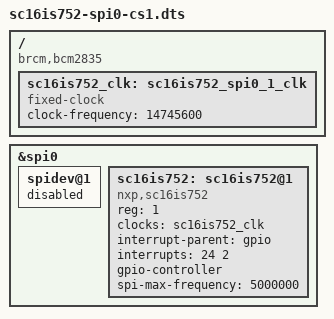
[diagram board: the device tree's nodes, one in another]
/dts-v1/;
/plugin/;

/ {
	compatible = "brcm,bcm2835";

	fragment@0 {
		target = <&spi0>;
		__overlay__ {
			#address-cells = <1>;
			#size-cells = <0>;
			status = "okay";
            
                        spidev@1{
                                status = "disabled";
                        };

			sc16is752: sc16is752@1 {
				compatible = "nxp,sc16is752";
				reg = <1>; /* CE0 */
				clocks = <&sc16is752_clk>;
				interrupt-parent = <&gpio>;
				interrupts = <24 2>; /* IRQ_TYPE_EDGE_FALLING */
				gpio-controller;
				#gpio-cells = <2>;
				spi-max-frequency = <5000000>;
			};
		};
	};


	fragment@1 {
		target-path = "/";
		__overlay__ {
			sc16is752_clk: sc16is752_spi0_1_clk {
				compatible = "fixed-clock";
				#clock-cells = <0>;
				clock-frequency = <14745600>;
			};
		};
	};

	__overrides__ {
		int_pin = <&sc16is752>,"interrupts:0";
		xtal = <&sc16is752_clk>,"clock-frequency:0";
		spi-max-frequency = <&sc16is752>,"spi-max-frequency:0";
	};
};
